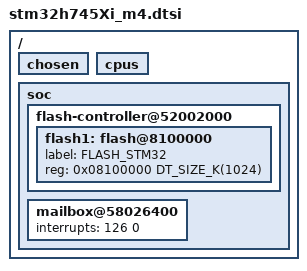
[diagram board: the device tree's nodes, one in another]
/*
 * Copyright (c) 2020 Alexander Kozhinov <AlexanderKozhinov@yandex.com>
 *
 * SPDX-License-Identifier: Apache-2.0
 */

#include <mem.h>
#include <st/h7/stm32h745.dtsi>

/delete-node/ &flash0;

/ {
	chosen {
		/* Flash controller support is not yet supported on M4 core */
		/delete-property/ zephyr,flash-controller;
	};

	cpus {
		/delete-node/ cpu@0;
	};

	soc {
		flash-controller@52002000 {
			flash1: flash@8100000 {
				label = "FLASH_STM32";
				reg = <0x08100000 DT_SIZE_K(1024)>;
			};
		};

		mailbox@58026400 {
			interrupts = <126 0>;
		};
	};
};
